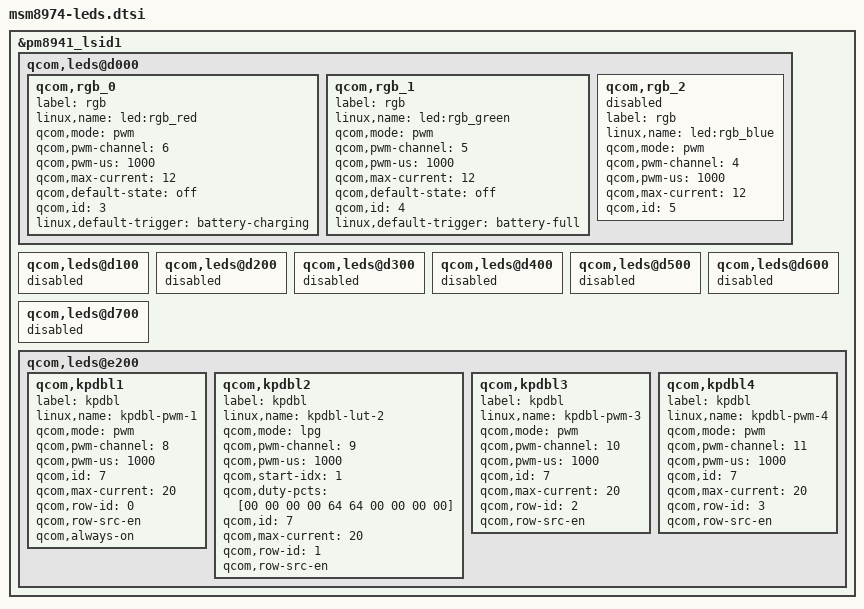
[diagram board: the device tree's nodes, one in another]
/*
 * Copyright (c) 2012-2013, The Linux Foundation. All rights reserved.
 *
 * This program is free software; you can redistribute it and/or modify
 * it under the terms of the GNU General Public License version 2 and
 * only version 2 as published by the Free Software Foundation.
 *
 * This program is distributed in the hope that it will be useful,
 * but WITHOUT ANY WARRANTY; without even the implied warranty of
 * MERCHANTABILITY or FITNESS FOR A PARTICULAR PURPOSE.  See the
 * GNU General Public License for more details.
 */

&pm8941_lsid1 {
	qcom,leds@d000 {
		status = "okay";
		qcom,rgb_0 {
			label = "rgb";
			linux,name = "led:rgb_red";
			qcom,mode = "pwm";
			qcom,pwm-channel = <6>;
			qcom,pwm-us = <1000>;
			qcom,max-current = <12>;
			qcom,default-state = "off";
			qcom,id = <3>;
			linux,default-trigger =
				"battery-charging";
		};

		qcom,rgb_1 {
			label = "rgb";
			linux,name = "led:rgb_green";
			qcom,mode = "pwm";
			qcom,pwm-channel = <5>;
			qcom,pwm-us = <1000>;
			qcom,max-current = <12>;
			qcom,default-state = "off";
			qcom,id = <4>;
			linux,default-trigger = "battery-full";
		};

		qcom,rgb_2 {
			label = "rgb";
			linux,name = "led:rgb_blue";
			qcom,mode = "pwm";
			qcom,pwm-channel = <4>;
			qcom,pwm-us = <1000>;
			qcom,max-current = <12>;
			qcom,id = <5>;
			status = "disabled";
		};
	};

	qcom,leds@d100 {
		status = "disabled";
	};

	qcom,leds@d200 {
		status = "disabled";
	};

	qcom,leds@d300 {
		status = "disabled";
	};

	qcom,leds@d400 {
		status = "disabled";
	};

	qcom,leds@d500 {
		status = "disabled";
	};

	qcom,leds@d600 {
		status = "disabled";
	};

	qcom,leds@d700 {
		status = "disabled";
	};

	qcom,leds@e200 {
		status = "okay";

		qcom,kpdbl1 {
			label = "kpdbl";
			linux,name = "kpdbl-pwm-1";
			qcom,mode = "pwm";
			qcom,pwm-channel = <8>;
			qcom,pwm-us = <1000>;
			qcom,id = <7>;
			qcom,max-current = <20>;
			qcom,row-id = <0>;
			qcom,row-src-en;
			qcom,always-on;
		};

		qcom,kpdbl2 {
			label = "kpdbl";
			linux,name = "kpdbl-lut-2";
			qcom,mode = "lpg";
			qcom,pwm-channel = <9>;
			qcom,pwm-us = <1000>;
			qcom,start-idx = <1>;
			qcom,duty-pcts = [00 00 00 00 64
					64 00 00 00 00];
			qcom,id = <7>;
			qcom,max-current = <20>;
			qcom,row-id = <1>;
			qcom,row-src-en;
		};

		qcom,kpdbl3 {
			label = "kpdbl";
			linux,name = "kpdbl-pwm-3";
			qcom,mode = "pwm";
			qcom,pwm-channel = <10>;
			qcom,pwm-us = <1000>;
			qcom,id = <7>;
			qcom,max-current = <20>;
			qcom,row-id = <2>;
			qcom,row-src-en;
		};

		qcom,kpdbl4 {
			label = "kpdbl";
			linux,name = "kpdbl-pwm-4";
			qcom,mode = "pwm";
			qcom,pwm-channel = <11>;
			qcom,pwm-us = <1000>;
			qcom,id = <7>;
			qcom,max-current = <20>;
			qcom,row-id = <3>;
			qcom,row-src-en;
		};
	};
};
